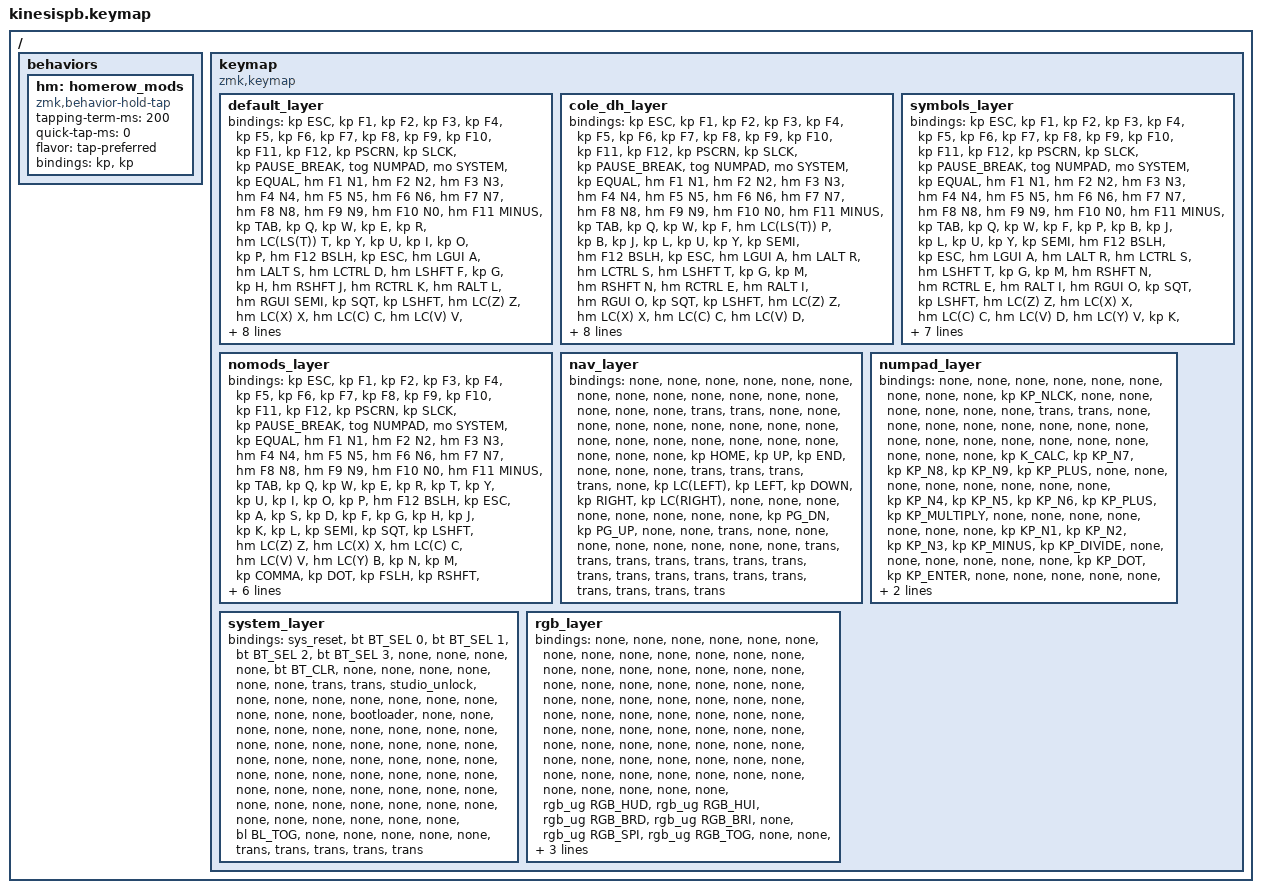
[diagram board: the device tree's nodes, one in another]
/*
 * Copyright (c) 2020 The ZMK Contributors
 *
 * SPDX-License-Identifier: MIT
 */
 
#define QWERTY 0
#define COLE_DH 1
#define SYMBOLS 2
#define NO_MODS 3
#define K_NAV_R 4
#define NUMPAD 5
#define SYSTEM 6
#define RGB_CTL 7

#include <behaviors.dtsi>
#include <dt-bindings/zmk/keys.h>
#include <dt-bindings/zmk/backlight.h>
#include <dt-bindings/zmk/bt.h>
#include <dt-bindings/zmk/outputs.h>
#include <dt-bindings/zmk/rgb.h>

/ {
    behaviors {
        hm: homerow_mods {
            compatible = "zmk,behavior-hold-tap";
            #binding-cells = <2>;
            tapping-term-ms = <200>;
            quick-tap-ms = <0>;
            flavor = "tap-preferred";
            bindings = <&kp>, <&kp>;
        };
    };

    keymap {
        compatible = "zmk,keymap";

    // Qwerty
        default_layer {
            bindings = <
    &kp ESC   &kp F1      &kp F2      &kp F3      &kp F4      &kp F5    &kp F6    &kp F7    &kp F8      &kp F9           &kp F10    &kp F11       &kp F12   &kp PSCRN  &kp SLCK  &kp PAUSE_BREAK  &tog NUMPAD  &mo SYSTEM
    &kp EQUAL &hm F1 N1   &hm F2 N2   &hm F3 N3   &hm F4 N4   &hm F5 N5           &hm F6 N6 &hm F7 N7   &hm F8 N8        &hm F9 N9  &hm F10 N0    &hm F11 MINUS
    &kp TAB   &kp Q       &kp W       &kp E       &kp R       &hm LC(LS(T)) T               &kp Y     &kp U       &kp I            &kp O      &kp P      &hm F12 BSLH
    &kp ESC   &hm LGUI A  &hm LALT S  &hm LCTRL D &hm LSHFT F &kp G               &kp H     &hm RSHFT J &hm RCTRL K      &hm RALT L &hm RGUI SEMI    &kp SQT
    &kp LSHFT &hm LC(Z) Z &hm LC(X) X &hm LC(C) C &hm LC(V) V &hm LC(Y) B         &kp N     &kp M       &kp COMMA        &kp DOT    &hm LC(FSLH) FSLH      &kp RSHFT
              &lt RGB_CTL GRAVE   &kp INSERT  &kp LEFT    &kp RIGHT                       &kp UP    &kp DOWN    &kp LBKT         &kp RBKT
                                                  &kp LCTRL   &kp LALT            &kp RGUI  &kp RCTRL
                                                              &kp HOME            &kp PG_UP
                                      &kp BSPC    &kp DEL     &kp END             &kp PG_DN &kp ENTER &kp SPACE
                                    &mo SYMBOLS                          &kp LSHFT &mo 2    &kp N3                    &mo K_NAV_R
            >;
        };

    // Colemak-DH
        cole_dh_layer {
            bindings = <
    &kp ESC   &kp F1      &kp F2      &kp F3      &kp F4      &kp F5    &kp F6    &kp F7    &kp F8      &kp F9           &kp F10    &kp F11       &kp F12   &kp PSCRN  &kp SLCK  &kp PAUSE_BREAK  &tog NUMPAD  &mo SYSTEM
    &kp EQUAL &hm F1 N1   &hm F2 N2   &hm F3 N3   &hm F4 N4   &hm F5 N5           &hm F6 N6 &hm F7 N7   &hm F8 N8        &hm F9 N9  &hm F10 N0    &hm F11 MINUS
    &kp TAB   &kp Q       &kp W       &kp F       &hm LC(LS(T)) P &kp B           &kp J     &kp L       &kp U            &kp Y      &kp SEMI      &hm F12 BSLH
    &kp ESC   &hm LGUI A  &hm LALT R  &hm LCTRL S &hm LSHFT T &kp G               &kp M     &hm RSHFT N &hm RCTRL E      &hm RALT I &hm RGUI O    &kp SQT
    &kp LSHFT &hm LC(Z) Z &hm LC(X) X &hm LC(C) C &hm LC(V) D &hm LC(Y) V         &kp K     &kp H       &kp COMMA        &kp DOT    &hm LC(FSLH) FSLH      &kp RSHFT
              &lt RGB_CTL GRAVE   &kp INSERT  &kp LEFT    &kp RIGHT                       &kp UP    &kp DOWN    &kp LBKT         &kp RBKT
                                                  &kp LCTRL   &kp LALT            &kp RGUI  &kp RCTRL
                                                              &kp HOME            &kp PG_UP
                                      &kp BSPC    &kp DEL     &kp END             &kp PG_DN &kp ENTER &kp SPACE
                                 &trans                             &trans &trans &trans                                &trans
            >;
        };

    // Symbols
        symbols_layer {
            bindings = <
    &kp ESC   &kp F1      &kp F2      &kp F3      &kp F4      &kp F5    &kp F6    &kp F7    &kp F8      &kp F9           &kp F10    &kp F11       &kp F12   &kp PSCRN  &kp SLCK  &kp PAUSE_BREAK  &tog NUMPAD  &mo SYSTEM
    &kp EQUAL &hm F1 N1   &hm F2 N2   &hm F3 N3   &hm F4 N4   &hm F5 N5           &hm F6 N6 &hm F7 N7   &hm F8 N8        &hm F9 N9  &hm F10 N0    &hm F11 MINUS
    &kp TAB   &kp Q       &kp W       &kp F       &kp P       &kp B               &kp J     &kp L       &kp U            &kp Y      &kp SEMI      &hm F12 BSLH
    &kp ESC   &hm LGUI A  &hm LALT R  &hm LCTRL S &hm LSHFT T &kp G               &kp M     &hm RSHFT N &hm RCTRL E      &hm RALT I &hm RGUI O    &kp SQT
    &kp LSHFT &hm LC(Z) Z &hm LC(X) X &hm LC(C) C &hm LC(V) D &hm LC(Y) V         &kp K     &kp H       &kp COMMA        &kp DOT    &kp FSLH      &kp RSHFT
              &lt RGB_CTL GRAVE   &kp INSERT  &kp LEFT    &kp RIGHT                       &kp UP    &kp DOWN    &kp LBKT         &kp RBKT
                                                  &kp LCTRL   &kp LALT            &kp RGUI  &kp RCTRL
                                                              &kp HOME            &kp PG_UP
                                      &kp BSPC    &kp DEL     &kp END             &kp PG_DN &kp ENTER &kp SPACE
                                 &trans                             &trans &trans &trans                                &trans
            >;
        };

    // Qwerty (No Mods)
        nomods_layer {
            bindings = <
    &kp ESC   &kp F1      &kp F2      &kp F3      &kp F4      &kp F5    &kp F6    &kp F7    &kp F8      &kp F9           &kp F10    &kp F11       &kp F12   &kp PSCRN  &kp SLCK  &kp PAUSE_BREAK  &tog NUMPAD  &mo SYSTEM
    &kp EQUAL &hm F1 N1   &hm F2 N2   &hm F3 N3   &hm F4 N4   &hm F5 N5           &hm F6 N6 &hm F7 N7   &hm F8 N8        &hm F9 N9  &hm F10 N0    &hm F11 MINUS
    &kp TAB   &kp Q       &kp W       &kp E       &kp R       &kp T               &kp Y     &kp U       &kp I            &kp O      &kp P      &hm F12 BSLH
    &kp ESC   &kp A       &kp S       &kp D       &kp F       &kp G               &kp H     &kp J       &kp K            &kp L      &kp SEMI    &kp SQT
    &kp LSHFT &hm LC(Z) Z &hm LC(X) X &hm LC(C) C &hm LC(V) V &hm LC(Y) B         &kp N     &kp M       &kp COMMA        &kp DOT    &kp FSLH      &kp RSHFT
              &lt RGB_CTL GRAVE   &kp INSERT  &kp LEFT    &kp RIGHT                       &kp UP    &kp DOWN    &kp LBKT         &kp RBKT
                                                  &kp LCTRL   &kp LALT            &kp RGUI  &kp RCTRL
                                                              &kp HOME            &kp PG_UP
                                      &kp BSPC    &kp DEL     &kp END             &kp PG_DN &kp ENTER &kp SPACE
                                 &trans                             &trans &trans &trans                                &trans
            >;
        };

    // Keyboard Navigation (Right side)
        nav_layer {
            bindings = <
    &none  &none  &none  &none  &none  &none  &none  &none  &none                                 &none         &none      &none     &none     &none         &none  &none  &trans  &trans
    &none  &none  &none  &none  &none  &none                                                      &none         &none      &none     &none     &none         &none
    &none  &none  &none  &none  &none  &none                                                      &none         &kp HOME   &kp UP    &kp END   &none         &none
    &none  &trans  &trans  &trans  &trans  &none                                                  &kp LC(LEFT)  &kp LEFT   &kp DOWN  &kp RIGHT &kp LC(RIGHT) &none
    &none  &none  &none  &none  &none  &none                                                      &none         &kp PG_DN  &kp PG_UP &none     &none         &trans
           &none  &none  &none  &none                                                             &none         &none      &none     &none
                                              &trans  &trans                                      &trans  &trans
                                                      &trans                                      &trans
                                       &trans  &trans &trans                                      &trans  &trans  &trans
                                 &trans                             &trans &trans &trans                                &trans
            >;
        };

    // Numpad
        numpad_layer {
            bindings = <
    &none  &none  &none  &none  &none  &none  &none  &none  &none                                 &kp KP_NLCK  &none  &none  &none  &none  &none  &none  &trans  &trans
    &none  &none  &none  &none  &none  &none                                                                   &none  &none        &none        &none        &none         &none
    &none  &none  &none  &none  &none  &none                                                                   &kp K_CALC  &kp KP_N7    &kp KP_N8    &kp KP_N9    &kp KP_PLUS  &none
    &none  &none  &none  &none  &none  &none                                                                   &none       &kp KP_N4    &kp KP_N5    &kp KP_N6    &kp KP_PLUS   &kp KP_MULTIPLY
    &none  &none  &none  &none  &none  &none                                                                   &none       &kp KP_N1    &kp KP_N2    &kp KP_N3    &kp KP_MINUS  &kp KP_DIVIDE
           &none  &none  &none  &none                                                                                 &none  &none  &kp KP_DOT  &kp KP_ENTER
                                              &none  &none                                        &none  &none
                                                     &none                                        &none
                                       &none  &none  &none                                        &none  &none  &kp KP_N0
                                 &trans                             &trans &trans &trans                                &trans
            >;
        };

    // System (Bluetooth & Bootloader)
        system_layer {
            bindings = <
    &sys_reset  &bt BT_SEL 0  &bt BT_SEL 1  &bt BT_SEL 2  &bt BT_SEL 3  &none  &none  &none  &none       &bt BT_CLR  &none  &none  &none  &none  &none  &none  &trans  &trans
    &studio_unlock  &none  &none  &none  &none  &none                                                          &none  &none  &none  &none  &none  &bootloader
    &none  &none  &none  &none  &none  &none                                                                   &none  &none  &none  &none  &none  &none
    &none  &none  &none  &none  &none  &none                                                                   &none  &none  &none  &none  &none  &none
    &none  &none  &none  &none  &none  &none                                                                   &none  &none  &none  &none  &none  &none
           &none  &none  &none  &none                                                                                 &none  &none  &none  &none
                                              &none  &none                                        &none  &none
                                                     &none                                        &none
                                  &bl BL_TOG  &none  &none                                        &none  &none  &none
                                 &trans                             &trans &trans &trans                                &trans
            >;
        };

    // RGB Backlighting control
        rgb_layer {
            bindings = <
    &none  &none  &none  &none  &none  &none  &none  &none  &none       &none  &none  &none  &none  &none  &none  &none  &none  &none
    &none  &none  &none  &none  &none  &none                                                                   &none  &none  &none  &none  &none  &none
    &none  &none  &none  &none  &none  &none                                                                   &none  &none  &none  &none  &none  &none
    &none  &none  &none  &none  &none  &none                                                                   &none  &none  &none  &none  &none  &none
    &none  &none  &none  &none  &none  &none                                                                   &none  &none  &none  &none  &none  &none
           &none  &none  &none  &none                                                                                 &none  &none  &none  &none
                                                &rgb_ug RGB_HUD  &rgb_ug RGB_HUI             &rgb_ug RGB_BRD  &rgb_ug RGB_BRI
                                                &none                                        &rgb_ug RGB_SPI
                                &rgb_ug RGB_TOG &none            &none                       &rgb_ug RGB_SPD  &rgb_ug RGB_EFR  &rgb_ug RGB_EFF
                                 &mo SYMBOLS                            &kp LSHFT       &mo 2       &kp N3                    &mo K_NAV_R
            >;
        };

    };
};
